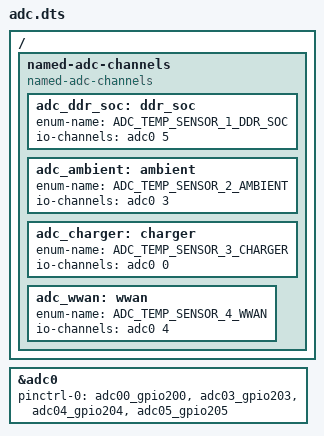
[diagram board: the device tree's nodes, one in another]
/* Copyright 2025 The ChromiumOS Authors
 * Use of this source code is governed by a BSD-style license that can be
 * found in the LICENSE file.
 */

/ {
	named-adc-channels {
		compatible = "named-adc-channels";

		adc_ddr_soc: ddr_soc {
			enum-name = "ADC_TEMP_SENSOR_1_DDR_SOC";
			io-channels = <&adc0 5>;
		};
		adc_ambient: ambient {
			enum-name = "ADC_TEMP_SENSOR_2_AMBIENT";
			io-channels = <&adc0 3>;
		};
		adc_charger: charger {
			enum-name = "ADC_TEMP_SENSOR_3_CHARGER";
			io-channels = <&adc0 0>;
		};
		adc_wwan: wwan {
			enum-name = "ADC_TEMP_SENSOR_4_WWAN";
			io-channels = <&adc0 4>;
		};
	};
};

&adc0 {
	status = "okay";
	pinctrl-0 = <&adc00_gpio200
		     &adc03_gpio203
		     &adc04_gpio204
		     &adc05_gpio205>;
	pinctrl-names = "default";
};

